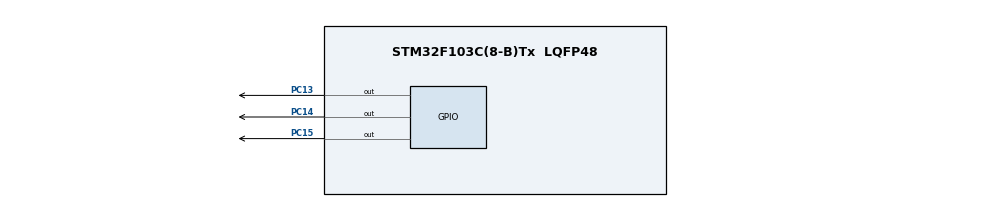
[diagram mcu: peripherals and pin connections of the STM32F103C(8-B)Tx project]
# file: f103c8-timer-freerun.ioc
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Mcu.Family=STM32F1
Mcu.Name=STM32F103C(8-B)Tx
Mcu.Package=LQFP48
NVIC.PriorityGroup=NVIC_PRIORITYGROUP_4
NVIC.TIM2_IRQn=true\:0\:0\:false\:false\:true\:true\:true
PA13.Mode=Serial_Wire
PA13.Signal=SYS_JTMS-SWDIO
PA14.Mode=Serial_Wire
PA14.Signal=SYS_JTCK-SWCLK
PC13-TAMPER-RTC.Signal=GPIO_Output
PC14-OSC32_IN.Signal=GPIO_Output
PC15-OSC32_OUT.Signal=GPIO_Output
PD0-OSC_IN.Mode=HSE-External-Oscillator
PD0-OSC_IN.Signal=RCC_OSC_IN
PD1-OSC_OUT.Mode=HSE-External-Oscillator
PD1-OSC_OUT.Signal=RCC_OSC_OUT
ProjectManager.HeapSize=0x200
ProjectManager.StackSize=0x400
ProjectManager.TargetToolchain=STM32CubeIDE
RCC.APB1Freq_Value=8000000
RCC.APB2Freq_Value=8000000
RCC.SYSCLKSource=RCC_SYSCLKSOURCE_HSE
TIM2.Period=65535
TIM2.Prescaler=7999
VP_TIM2_VS_ClockSourceINT.Mode=Internal
board=custom

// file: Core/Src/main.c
/* USER CODE BEGIN Header */
/**
  ******************************************************************************
  * @file           : main.c
  * @brief          : Main program body
  ******************************************************************************
  * @attention
  *
  * <h2><center>&copy; Copyright (c) 2021 STMicroelectronics.
  * All rights reserved.</center></h2>
  *
  * This software component is licensed by ST under BSD 3-Clause license,
  * the "License"; You may not use this file except in compliance with the
  * License. You may obtain a copy of the License at:
  *                        opensource.org/licenses/BSD-3-Clause
  *
  ******************************************************************************
  */
/* USER CODE END Header */
#include "main.h"

/* USER CODE BEGIN PD */
#define ADD_DUMMY_TASK_DELAY    1
/* USER CODE END PD */

void SystemClock_Config(void);
static void MX_GPIO_Init(void);
static void MX_TIM2_Init(void);

int main(void)
{

  /* MCU Configuration--------------------------------------------------------*/

  /* Reset of all peripherals, Initializes the Flash interface and the Systick. */
  HAL_Init();

  /* Configure the system clock */
  SystemClock_Config();

  /* Initialize all configured peripherals */
  MX_GPIO_Init();
  MX_TIM2_Init();
  /* USER CODE BEGIN 2 */

  LL_TIM_EnableCounter(TIM2);

  /* USER CODE END 2 */

  /* Infinite loop */
  /* USER CODE BEGIN WHILE */
  uint16_t last_time = 0;
  while (1)
  {
#if ADD_DUMMY_TASK_DELAY
      // Do something between 5-15 ms
      srand(HAL_GetTick());
      HAL_Delay((rand() % 10) + 5);
#endif
      uint16_t current_time = LL_TIM_GetCounter(TIM2);
      if (current_time - last_time >= 100)
      {
          last_time = current_time;
          HAL_GPIO_TogglePin(GPIOC, GPIO_PIN_15);
      }
    /* USER CODE END WHILE */

  }
}

void SystemClock_Config(void)
{
  RCC_OscInitTypeDef RCC_OscInitStruct = {0};
  RCC_ClkInitTypeDef RCC_ClkInitStruct = {0};

  /** Initializes the RCC Oscillators according to the specified parameters
  * in the RCC_OscInitTypeDef structure.
  */
  RCC_OscInitStruct.OscillatorType = RCC_OSCILLATORTYPE_HSE;
  RCC_OscInitStruct.HSEState = RCC_HSE_ON;
  RCC_OscInitStruct.PLL.PLLState = RCC_PLL_NONE;
  if (HAL_RCC_OscConfig(&RCC_OscInitStruct) != HAL_OK)
  {
    Error_Handler();
  }
  /** Initializes the CPU, AHB and APB buses clocks
  */
  RCC_ClkInitStruct.ClockType = RCC_CLOCKTYPE_HCLK|RCC_CLOCKTYPE_SYSCLK
                              |RCC_CLOCKTYPE_PCLK1|RCC_CLOCKTYPE_PCLK2;
  RCC_ClkInitStruct.SYSCLKSource = RCC_SYSCLKSOURCE_HSE;
  RCC_ClkInitStruct.AHBCLKDivider = RCC_SYSCLK_DIV1;
  RCC_ClkInitStruct.APB1CLKDivider = RCC_HCLK_DIV1;
  RCC_ClkInitStruct.APB2CLKDivider = RCC_HCLK_DIV1;

  if (HAL_RCC_ClockConfig(&RCC_ClkInitStruct, FLASH_LATENCY_0) != HAL_OK)
  {
    Error_Handler();
  }
}

static void MX_TIM2_Init(void)
{

  LL_TIM_InitTypeDef TIM_InitStruct = {0};

  /* Peripheral clock enable */
  LL_APB1_GRP1_EnableClock(LL_APB1_GRP1_PERIPH_TIM2);

  /* TIM2 interrupt Init */
  NVIC_SetPriority(TIM2_IRQn, NVIC_EncodePriority(NVIC_GetPriorityGrouping(),0, 0));
  NVIC_EnableIRQ(TIM2_IRQn);

  TIM_InitStruct.Prescaler = 7999;
  TIM_InitStruct.CounterMode = LL_TIM_COUNTERMODE_UP;
  TIM_InitStruct.Autoreload = 65535;
  TIM_InitStruct.ClockDivision = LL_TIM_CLOCKDIVISION_DIV1;
  LL_TIM_Init(TIM2, &TIM_InitStruct);
  LL_TIM_DisableARRPreload(TIM2);
  LL_TIM_SetClockSource(TIM2, LL_TIM_CLOCKSOURCE_INTERNAL);
  LL_TIM_SetTriggerOutput(TIM2, LL_TIM_TRGO_RESET);
  LL_TIM_DisableMasterSlaveMode(TIM2);

}

static void MX_GPIO_Init(void)
{
  GPIO_InitTypeDef GPIO_InitStruct = {0};

  /* GPIO Ports Clock Enable */
  __HAL_RCC_GPIOC_CLK_ENABLE();
  __HAL_RCC_GPIOD_CLK_ENABLE();
  __HAL_RCC_GPIOA_CLK_ENABLE();

  /*Configure GPIO pin Output Level */
  HAL_GPIO_WritePin(GPIOC, GPIO_PIN_13|GPIO_PIN_14|GPIO_PIN_15, GPIO_PIN_RESET);

  /*Configure GPIO pins : PC13 PC14 PC15 */
  GPIO_InitStruct.Pin = GPIO_PIN_13|GPIO_PIN_14|GPIO_PIN_15;
  GPIO_InitStruct.Mode = GPIO_MODE_OUTPUT_PP;
  GPIO_InitStruct.Pull = GPIO_NOPULL;
  GPIO_InitStruct.Speed = GPIO_SPEED_FREQ_LOW;
  HAL_GPIO_Init(GPIOC, &GPIO_InitStruct);

}

void Error_Handler(void)
{
  __disable_irq();
  while (1)
  {
  }
}

/************************ (C) COPYRIGHT STMicroelectronics *****END OF FILE****/
